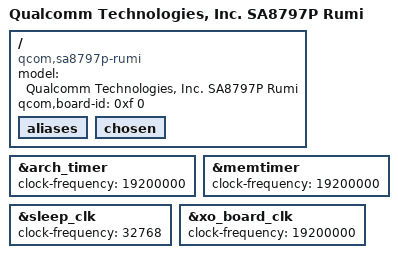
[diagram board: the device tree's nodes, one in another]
// SPDX-License-Identifier: BSD-3-Clause
/*
 * Copyright (c) 2024 Qualcomm Innovation Center, Inc. All rights reserved.
 */

/dts-v1/;

#include "sa8797p.dtsi"
/ {
	model = "Qualcomm Technologies, Inc. SA8797P Rumi";
	compatible = "qcom,sa8797p-rumi", "qcom,sa8797p";
	qcom,board-id = <0xf 0>;

	aliases { };

	chosen { };
};

&arch_timer {
	clock-frequency = <19200000>;
};

&memtimer {
	clock-frequency = <19200000>;
};

&sleep_clk {
	clock-frequency = <32768>;
};

&xo_board_clk {
	clock-frequency = <19200000>;
};
